AUTOSAR XML (schema 4-3-0)
standard types defined: boolean, uint16, uint32, uint64, uint8, boolean_DataConstr, uint16_DataConstr, uint32_DataConstr, uint64_DataConstr, uint8_DataConstr
package /ComponentTypes/MappingSets
  data type mapping set APP_data_mapping
    data-type-maps:
      application-data-type=APP_CallID, implementation-data-type=uint64
      application-data-type=App_Curr, implementation-data-type=uint16
      application-data-type=App_DutyRat, implementation-data-type=uint16
      application-data-type=App_FltSts, implementation-data-type=uint8
      application-data-type=App_HornActSts, implementation-data-type=uint8
      application-data-type=App_HornCmd, implementation-data-type=uint8
      application-data-type=APP_HornCtrlMode1, implementation-data-type=Impl_HornCtrlMode1
      application-data-type=App_HornHonkMode, implementation-data-type=uint8
      application-data-type=App_HornOperCmd, implementation-data-type=uint8
      application-data-type=APP_HornPeriodMode, implementation-data-type=Impl_HornPeriod
      application-data-type=APP_HornTimes, implementation-data-type=uint8
      application-data-type=APP_OffDuration, implementation-data-type=uint32
      application-data-type=APP_OnDuration, implementation-data-type=uint32
      application-data-type=APP_OperSts, implementation-data-type=uint8
      application-data-type=APP_Prio, implementation-data-type=uint8
      application-data-type=App_ReturnCode, implementation-data-type=uint8
      application-data-type=App_SrvOperSts1, implementation-data-type=Impl_SrvOperSts_Struct
      application-data-type=APP_TimeStamp, implementation-data-type=uint64
      application-data-type=App_Volt, implementation-data-type=uint16
      application-data-type=APP_Boolean, implementation-data-type=boolean
      application-data-type=APP_Uint8, implementation-data-type=uint8
package /DataTypes
  10 x app type, all with sw-calibration-access=READ-ONLY:
    APP_Boolean: category=BOOLEAN, compu {0=FALSE, 1=TRUE}
    APP_CallID: category=VALUE
    App_HornHonkMode: category=VALUE, compu {0=STOP, 1=START, 2=ALERT, 255=INVALID}
    APP_HornTimes: category=VALUE
    APP_OffDuration: category=VALUE
    APP_OnDuration: category=VALUE
    APP_OperSts: category=VALUE
    APP_Prio: category=VALUE
    APP_TimeStamp: category=VALUE
    APP_Uint8: category=VALUE
  application record data type APP_HornCtrlMode1: category=STRUCTURE, sw-calibration-access=READ-ONLY
    5 x application record element:
      CallID: category=VALUE, type=APP_CallID
      TimeStamp: category=VALUE, type=APP_TimeStamp
      Prio: category=VALUE, type=APP_Prio
      HornHonkMode: category=VALUE, type=App_HornHonkMode
      HornPeriodMode: category=STRUCTURE, type=APP_HornPeriodMode
  application record data type APP_HornPeriodMode: category=STRUCTURE, sw-calibration-access=READ-ONLY
    application record element OnDuration: category=VALUE, type=APP_OnDuration
    application record element OffDuration: category=VALUE, type=APP_OffDuration
    application record element HornTimes: category=VALUE, type=APP_HornTimes
  application record data type App_SrvOperSts1: category=STRUCTURE, sw-calibration-access=READ-ONLY
    4 x application record element, all with category=VALUE:
      CallID: type=APP_CallID
      TimeStamp: type=APP_TimeStamp
      Prio: type=APP_Prio
      OperSts: type=APP_OperSts
  impl type Impl_HornCtrlMode1: category=STRUCTURE, sw-calibration-access=READ-ONLY, type-emitter=RTE
    5 x element, all with category=TYPE_REFERENCE:
      CallID: implementation-data-type=uint64
      TimeStamp: implementation-data-type=uint64
      Prio: implementation-data-type=uint8
      HornHonkMode: compu {0=STOP, 1=START, 2=ALERT, 255=INVALID}, implementation-data-type=uint8
      HornPeriodMode: implementation-data-type=Impl_HornPeriod
  impl type Impl_HornPeriod: category=STRUCTURE, sw-calibration-access=READ-ONLY, type-emitter=RTE
    element OnDuration: implementation-data-type=uint32
    element OffDuration: implementation-data-type=uint32
    element HornTimes: compu {0=0次 (zero), 1=1次 (one), 2=2次 (two), 255=Invalid}, implementation-data-type=uint8
package /HORN_CTRL/ApplicationDataTypes
  8 x app type, all with category=VALUE:
    App_Curr: compu {phys=raw*0.01 for raw 0..65535; unit A}, range raw 0..65535, unit=A
    App_DutyRat: compu {phys=raw*0.1 for raw 0..1000}, range raw 0..1000, unit=-
    App_FltSts
    App_HornActSts: compu {0=HONK_OFF, 1=HONK_ON, 255=INVALID}, range raw 0..255, unit=-
    App_HornCmd: compu {0=STOP, 1=START, 2=ALERT, 255=INVALID}, range raw 0..255
    App_HornOperCmd: compu {0=OFF, 1=ON, 255=INVALID}, range raw 0..255
    App_ReturnCode
    App_Volt: compu {phys=raw*0.01 for raw 0..65535; unit V}, range raw 0..65535, unit=V
package /HORN_CTRL/Components
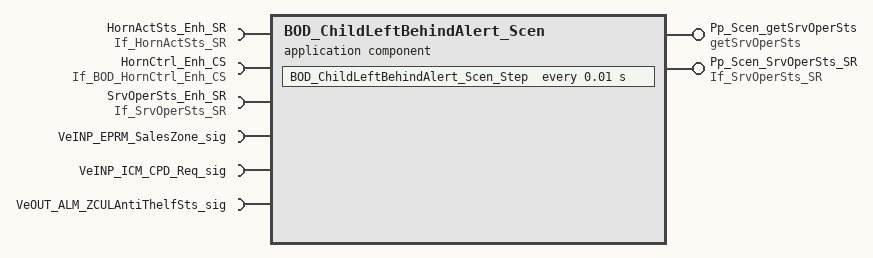
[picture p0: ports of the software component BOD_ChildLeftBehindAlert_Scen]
  application sw component type BOD_ChildLeftBehindAlert_Scen
    provide port Pp_Scen_getSrvOperSts: server-com-spec{operation=getSrvOperSts/getSrvOperSts, queue-length=1}, provided-interface=getSrvOperSts
    provide port Pp_Scen_SrvOperSts_SR: nonqueued-sender-com-spec{data-element=ntfSrvOperSts, init-value=fields=[CallID:0, TimeStamp:0, Prio:0, OperSts:0]}, provided-interface=If_SrvOperSts_SR
    6 x require port:
      HornActSts_Enh_SR: nonqueued-receiver-com-spec{data-element=ntfHornActSts, filter=data-filter-type=ALWAYS, init-value=0}, required-interface=If_HornActSts_SR
      HornCtrl_Enh_CS: required-interface=If_BOD_HornCtrl_Enh_CS
        required-com-specs:
          operation=getHornActSts, end-to-end-transformation-com-spec-props=disable-end-to-end-check=false
          operation=If_BOD_HornCtrl_Enh_CS/getSrvOperSts, end-to-end-transformation-com-spec-props=disable-end-to-end-check=false
          operation=rrHornCtrl, end-to-end-transformation-com-spec-props=disable-end-to-end-check=false
      SrvOperSts_Enh_SR: nonqueued-receiver-com-spec{data-element=ntfSrvOperSts, filter=data-filter-type=ALWAYS, init-value=fields=[TimeStamp:0, CallID:0, Prio:0, OperSts:0]}, required-interface=If_SrvOperSts_SR
      VeINP_EPRM_SalesZone_sig: nonqueued-receiver-com-spec{data-element=VeINP_EPRM_SalesZone_sig, filter=data-filter-type=ALWAYS, init-value=0}, required-interface=VeINP_EPRM_SalesZone_sig
      VeINP_ICM_CPD_Req_sig: nonqueued-receiver-com-spec{data-element=VeINP_ICM_CPD_Req_sig, filter=data-filter-type=ALWAYS, init-value=0}, required-interface=VeINP_ICM_CPD_Req_sig
      VeOUT_ALM_ZCULAntiThelfSts_sig: nonqueued-receiver-com-spec{data-element=VeOUT_ALM_ZCULAntiThelfSts_sig, filter=data-filter-type=ALWAYS, init-value=0}, required-interface=VeOUT_ALM_ZCULAntiThelfSts_sig
    behavior BOD_ChildLeftBehindAlert_Scen_InternalBehavior: data-type-mapping=APP_data_mapping, handle-termination-and-restart=NO-SUPPORT
      init event BOD_ChildLeftBehindAlert_Scen_InitEvent: start-on-event=BOD_ChildLeftBehindAlert_Scen_Init
      timing event TMT_BOD_ChildLeftBehindAlert_Scen_Step: start-on-event=BOD_ChildLeftBehindAlert_Scen_Step, period=0.01
      operation invoked event OIT_Pp_Scen_getSrvOperSts_getSrvOperSts_Pp_Scen_getSrvOperSts_getSrvOperSts: start-on-event=Pp_Scen_getSrvOperSts_getSrvOperSts, operation=Pp_Scen_getSrvOperSts.getSrvOperSts
      data received event DRT_Runnable_NTF_Pp_HornActSts_SR_ntfHornActSts: start-on-event=BOD_ChildLeftBehindAlert_Scen_InternalBehavior/Runnable_NTF, data=HornActSts_Enh_SR.ntfHornActSts
      data received event DRT_Runnable_NTF_Rp_SrvOperSts_SR_ntfSrvOperSts: start-on-event=BOD_ChildLeftBehindAlert_Scen_InternalBehavior/Runnable_NTF, data=SrvOperSts_Enh_SR.ntfSrvOperSts
      4 x runnable:
        BOD_ChildLeftBehindAlert_Scen_Init
        BOD_ChildLeftBehindAlert_Scen_Step
          data-receive-point-by-arguments:
            access REC_VeINP_EPRM_SalesZone_sig_VeINP_EPRM_SalesZone_sig: accessed-variable=VeINP_EPRM_SalesZone_sig.VeINP_EPRM_SalesZone_sig
            access REC_VeINP_ICM_CPD_Req_sig_VeINP_ICM_CPD_Req_sig: accessed-variable=VeINP_ICM_CPD_Req_sig.VeINP_ICM_CPD_Req_sig
            access REC_VeOUT_ALM_ZCULAntiThelfSts_sig_VeOUT_ALM_ZCULAntiThelfSts_sig: accessed-variable=VeOUT_ALM_ZCULAntiThelfSts_sig.VeOUT_ALM_ZCULAntiThelfSts_sig
          data-send-points:
            access SEND_Pp_SrvOperSts_SR_ntfSrvOperSts: accessed-variable=Pp_Scen_SrvOperSts_SR.ntfSrvOperSts
          sync call SC_Rp_HornCtrl_Enh_CS_getHornActSts: operation=HornCtrl_Enh_CS.getHornActSts, timeout=0
          sync call SC_Rp_HornCtrl_Enh_CS_getSrvOperSts: operation=HornCtrl_Enh_CS.getSrvOperSts, timeout=0
          sync call SC_Rp_HornCtrl_Enh_CS_rrHornCtrl: operation=HornCtrl_Enh_CS.rrHornCtrl, timeout=0
        Pp_Scen_getSrvOperSts_getSrvOperSts
        Runnable_NTF
          data-receive-point-by-arguments:
            access REC_Pp_HornActSts_SR_ntfHornActSts: accessed-variable=HornActSts_Enh_SR.ntfHornActSts
            access REC_Rp_SrvOperSts_SR_ntfSrvOperSts: accessed-variable=SrvOperSts_Enh_SR.ntfSrvOperSts
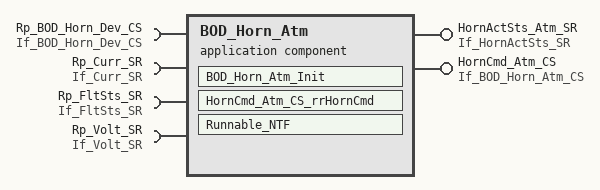
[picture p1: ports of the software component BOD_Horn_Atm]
  application sw component type BOD_Horn_Atm
    provide port HornActSts_Atm_SR: nonqueued-sender-com-spec{data-element=ntfHornActSts, init-value=0}, provided-interface=If_HornActSts_SR
    provide port HornCmd_Atm_CS: server-com-spec{operation=rrHornCmd, queue-length=1, end-to-end-transformation-com-spec-props=disable-end-to-end-check=false}, provided-interface=If_BOD_Horn_Atm_CS
    4 x require port:
      Rp_BOD_Horn_Dev_CS: client-com-spec=operation=rrHornOperCmd, required-interface=If_BOD_Horn_Dev_CS
      Rp_Curr_SR: nonqueued-receiver-com-spec{data-element=ntfCurr, filter=data-filter-type=ALWAYS, init-value=0}, required-interface=If_Curr_SR
      Rp_FltSts_SR: nonqueued-receiver-com-spec{data-element=ntfFltSts, filter=data-filter-type=ALWAYS, init-value=0}, required-interface=If_FltSts_SR
      Rp_Volt_SR: nonqueued-receiver-com-spec{data-element=ntfVolt, filter=data-filter-type=ALWAYS, init-value=0}, required-interface=If_Volt_SR
    behavior IB_BOD_Horn_Atm: data-type-mapping=APP_data_mapping, handle-termination-and-restart=NO-SUPPORT
      init event BOD_Horn_Atm_InitEvent: start-on-event=BOD_Horn_Atm_Init
      operation invoked event OIT_HornCmd_Atm_CS_rrHornCmd_HornCmd_Atm_CS_rrHornCmd: start-on-event=HornCmd_Atm_CS_rrHornCmd, operation=HornCmd_Atm_CS.rrHornCmd
      data received event DRT_Runnable_NTF_Rp_Curr_SR_ntfCurr: start-on-event=IB_BOD_Horn_Atm/Runnable_NTF, data=Rp_Curr_SR.ntfCurr
      data received event DRT_Runnable_NTF_Rp_FltSts_SR_ntfFltSts: start-on-event=IB_BOD_Horn_Atm/Runnable_NTF, data=Rp_FltSts_SR.ntfFltSts
      data received event DRT_Runnable_NTF_Rp_Volt_SR_ntfVolt: start-on-event=IB_BOD_Horn_Atm/Runnable_NTF, data=Rp_Volt_SR.ntfVolt
      runnable BOD_Horn_Atm_Init
      runnable HornCmd_Atm_CS_rrHornCmd
      runnable Runnable_NTF
        data-receive-point-by-arguments:
          access REC_Rp_Curr_SR_ntfCurr: accessed-variable=Rp_Curr_SR.ntfCurr
          access REC_Rp_FltSts_SR_ntfFltSts: accessed-variable=Rp_FltSts_SR.ntfFltSts
          access REC_Rp_Volt_SR_ntfVolt: accessed-variable=Rp_Volt_SR.ntfVolt
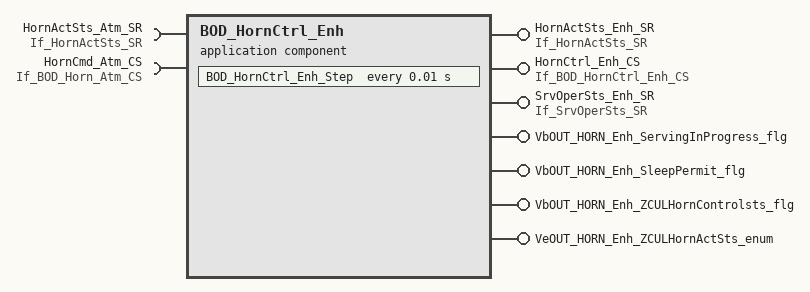
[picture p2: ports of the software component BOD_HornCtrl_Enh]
  application sw component type BOD_HornCtrl_Enh
    7 x provide port:
      HornActSts_Enh_SR: nonqueued-sender-com-spec{data-element=ntfHornActSts, transmission-acknowledge=timeout=0.5, init-value=0}, provided-interface=If_HornActSts_SR
      HornCtrl_Enh_CS: provided-interface=If_BOD_HornCtrl_Enh_CS
        provided-com-specs:
          operation=getHornActSts, queue-length=1, end-to-end-transformation-com-spec-props=disable-end-to-end-check=false
          operation=If_BOD_HornCtrl_Enh_CS/getSrvOperSts, queue-length=1, end-to-end-transformation-com-spec-props=disable-end-to-end-check=false
          operation=rrHornCtrl, queue-length=1, end-to-end-transformation-com-spec-props=disable-end-to-end-check=false
      SrvOperSts_Enh_SR: nonqueued-sender-com-spec{data-element=ntfSrvOperSts, handle-out-of-range=DEFAULT, transmission-acknowledge=timeout=0, init-value=fields=[TimeStamp:0, CallID:0, Prio:0, OperSts:0]}, provided-interface=If_SrvOperSts_SR
      VbOUT_HORN_Enh_ServingInProgress_flg: nonqueued-sender-com-spec{data-element=VbOUT_HORN_Enh_ServingInProgress_flg, init-value=0}, provided-interface=VbOUT_HORN_Enh_ServingInProgress_flg
      VbOUT_HORN_Enh_SleepPermit_flg: nonqueued-sender-com-spec{data-element=VbOUT_HORN_Enh_SleepPermit_flg, init-value=0}, provided-interface=VbOUT_HORN_Enh_SleepPermit_flg
      VbOUT_HORN_Enh_ZCULHornControlsts_flg: nonqueued-sender-com-spec{data-element=VbOUT_HORN_Enh_ZCULHornControlsts_flg, init-value=0}, provided-interface=VbOUT_HORN_Enh_ZCULHornControlsts_flg
      VeOUT_HORN_Enh_ZCULHornActSts_enum: nonqueued-sender-com-spec{data-element=VeOUT_HORN_Enh_ZCULHornActSts_enum, init-value=0}, provided-interface=VeOUT_HORN_Enh_ZCULHornActSts_enum
    require port HornActSts_Atm_SR: nonqueued-receiver-com-spec{data-element=ntfHornActSts, filter=data-filter-type=ALWAYS, init-value=0}, required-interface=If_HornActSts_SR
    require port HornCmd_Atm_CS: client-com-spec{operation=rrHornCmd, end-to-end-transformation-com-spec-props=disable-end-to-end-check=false}, required-interface=If_BOD_Horn_Atm_CS
    behavior IB_BOD_HornCtrl_Enh: data-type-mapping=APP_data_mapping, handle-termination-and-restart=NO-SUPPORT
      init event BOD_HornCtrl_Enh_InitEvent: start-on-event=BOD_HornCtrl_Enh_Init
      timing event TMT_Runnable: start-on-event=BOD_HornCtrl_Enh_Step, period=0.01
      operation invoked event OIT_HornCtrl_Enh_CS_getHornActSts_HornCtrl_Enh_CS_getHornActSts: start-on-event=HornCtrl_Enh_CS_getHornActSts, operation=HornCtrl_Enh_CS.getHornActSts
      operation invoked event OIT_HornCtrl_Enh_CS_getSrvOperSts_HornCtrl_Enh_CS_getSrvOperSts: start-on-event=HornCtrl_Enh_CS_getSrvOperSts, operation=HornCtrl_Enh_CS.getSrvOperSts
      operation invoked event OIT_HornCtrl_Enh_CS_rrHornCtrl_HornCtrl_Enh_CS_rrHornCtrl: start-on-event=HornCtrl_Enh_CS_rrHornCtrl, operation=HornCtrl_Enh_CS.rrHornCtrl
      data received event DRT_Runnable_NTF_Rp_Horn_Atm_SR_ntfHornActSts: start-on-event=IB_BOD_HornCtrl_Enh/Runnable_NTF, data=HornActSts_Atm_SR.ntfHornActSts
      6 x runnable:
        BOD_HornCtrl_Enh_Init
        BOD_HornCtrl_Enh_Step
          data-send-points:
            6 x access:
              SEND_Pp_HornActSts_SR_ntfHornActSts: accessed-variable=HornActSts_Enh_SR.ntfHornActSts
              SEND_Pp_SrvOperSts_SR_ntfSrvOperSts: accessed-variable=SrvOperSts_Enh_SR.ntfSrvOperSts
              SEND_VbOUT_HORN_Enh_ServingInProgress_flg_VbOUT_HORN_Enh_ServingInProgress_flg: accessed-variable=VbOUT_HORN_Enh_ServingInProgress_flg.VbOUT_HORN_Enh_ServingInProgress_flg
              SEND_VbOUT_HORN_Enh_SleepPermit_flg_VbOUT_HORN_Enh_SleepPermit_flg: accessed-variable=VbOUT_HORN_Enh_SleepPermit_flg.VbOUT_HORN_Enh_SleepPermit_flg
              SEND_VbOUT_HORN_Enh_ZCULHornControlsts_flg_VbOUT_HORN_Enh_ZCULHornControlsts_flg: accessed-variable=VbOUT_HORN_Enh_ZCULHornControlsts_flg.VbOUT_HORN_Enh_ZCULHornControlsts_flg
              SEND_VeOUT_HORN_Enh_ZCULHornActSts_enum_VeOUT_HORN_Enh_ZCULHornActSts_enum: accessed-variable=VeOUT_HORN_Enh_ZCULHornActSts_enum.VeOUT_HORN_Enh_ZCULHornActSts_enum
          sync call SC_Rp_Horn_Atm_CS_rrHornCmd: operation=HornCmd_Atm_CS.rrHornCmd, timeout=0
        HornCtrl_Enh_CS_getHornActSts
        HornCtrl_Enh_CS_getSrvOperSts
        HornCtrl_Enh_CS_rrHornCtrl
        Runnable_NTF
          data-receive-point-by-arguments:
            access REC_Rp_Horn_Atm_SR_ntfHornActSts: accessed-variable=HornActSts_Atm_SR.ntfHornActSts
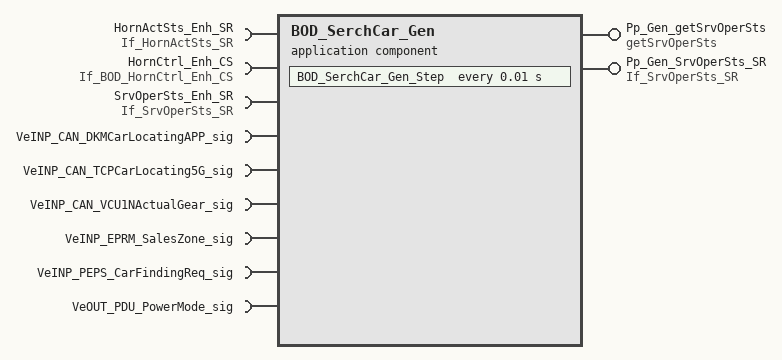
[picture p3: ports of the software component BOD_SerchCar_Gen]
  application sw component type BOD_SerchCar_Gen
    provide port Pp_Gen_getSrvOperSts: server-com-spec{operation=getSrvOperSts/getSrvOperSts, queue-length=1}, provided-interface=getSrvOperSts
    provide port Pp_Gen_SrvOperSts_SR: nonqueued-sender-com-spec{data-element=ntfSrvOperSts, init-value=fields=[CallID:0, TimeStamp:0, Prio:0, OperSts:0]}, provided-interface=If_SrvOperSts_SR
    9 x require port:
      HornActSts_Enh_SR: nonqueued-receiver-com-spec{data-element=ntfHornActSts, filter=data-filter-type=ALWAYS, init-value=0}, required-interface=If_HornActSts_SR
      HornCtrl_Enh_CS: required-interface=If_BOD_HornCtrl_Enh_CS
        required-com-specs:
          operation=getHornActSts, end-to-end-transformation-com-spec-props=disable-end-to-end-check=false
          operation=If_BOD_HornCtrl_Enh_CS/getSrvOperSts, end-to-end-transformation-com-spec-props=disable-end-to-end-check=false
          operation=rrHornCtrl, end-to-end-transformation-com-spec-props=disable-end-to-end-check=false
      SrvOperSts_Enh_SR: nonqueued-receiver-com-spec{data-element=ntfSrvOperSts, filter=data-filter-type=ALWAYS, init-value=fields=[TimeStamp:0, CallID:0, Prio:0, OperSts:0]}, required-interface=If_SrvOperSts_SR
      VeINP_CAN_DKMCarLocatingAPP_sig: nonqueued-receiver-com-spec{data-element=VeINP_CAN_DKMCarLocatingAPP_sig, filter=data-filter-type=ALWAYS, init-value=0}, required-interface=VeINP_CAN_DKMCarLocatingAPP_sig
      VeINP_CAN_TCPCarLocating5G_sig: nonqueued-receiver-com-spec{data-element=VeINP_CAN_TCPCarLocating5G_sig, filter=data-filter-type=ALWAYS, init-value=0}, required-interface=VeINP_CAN_TCPCarLocating5G_sig
      VeINP_CAN_VCU1NActualGear_sig: nonqueued-receiver-com-spec{data-element=VeINP_CAN_VCU1NActualGear_sig, filter=data-filter-type=ALWAYS, init-value=0}, required-interface=VeINP_CAN_VCU1NActualGear_sig
      VeINP_EPRM_SalesZone_sig: nonqueued-receiver-com-spec{data-element=VeINP_EPRM_SalesZone_sig, filter=data-filter-type=ALWAYS, init-value=0}, required-interface=VeINP_EPRM_SalesZone_sig
      VeINP_PEPS_CarFindingReq_sig: nonqueued-receiver-com-spec{data-element=VeINP_PEPS_CarFindingReq_sig, filter=data-filter-type=ALWAYS, init-value=0}, required-interface=VeINP_PEPS_CarFindingReq_sig
      VeOUT_PDU_PowerMode_sig: nonqueued-receiver-com-spec{data-element=VeOUT_PDU_PowerMode_sig, filter=data-filter-type=ALWAYS, init-value=0}, required-interface=VeOUT_PDU_PowerMode_sig
    behavior BOD_SerchCar_Gen_InternalBehavior: data-type-mapping=APP_data_mapping, handle-termination-and-restart=NO-SUPPORT
      init event BOD_SerchCar_Gen_InitEvent: start-on-event=BOD_SerchCar_Gen_Init
      timing event TMT_Runnable_1: start-on-event=BOD_SerchCar_Gen_Step, period=0.01
      operation invoked event OIT_Pp_Gen_getSrvOperSts_getSrvOperSts_Pp_Gen_getSrvOperSts_getSrvOperSts: start-on-event=Pp_Gen_getSrvOperSts_getSrvOperSts, operation=Pp_Gen_getSrvOperSts.getSrvOperSts
      data received event DRT_Runnable_Rp_HornActSts_SR_ntfHornActSts: start-on-event=BOD_SerchCar_Gen_InternalBehavior/Runnable_NTF, data=HornActSts_Enh_SR.ntfHornActSts
      data received event DRT_Runnable_Rp_SrvOperSts_SR_ntfSrvOperSts: start-on-event=BOD_SerchCar_Gen_InternalBehavior/Runnable_NTF, data=SrvOperSts_Enh_SR.ntfSrvOperSts
      4 x runnable:
        BOD_SerchCar_Gen_Init
        BOD_SerchCar_Gen_Step
          data-receive-point-by-arguments:
            6 x access:
              REC_VeINP_CAN_DKMCarLocatingAPP_sig_VeINP_CAN_DKMCarLocatingAPP_sig: accessed-variable=VeINP_CAN_DKMCarLocatingAPP_sig.VeINP_CAN_DKMCarLocatingAPP_sig
              REC_VeINP_CAN_TCPCarLocating5G_sig_VeINP_CAN_TCPCarLocating5G_sig: accessed-variable=VeINP_CAN_TCPCarLocating5G_sig.VeINP_CAN_TCPCarLocating5G_sig
              REC_VeINP_CAN_VCU1NActualGear_sig_VeINP_CAN_VCU1NActualGear_sig: accessed-variable=VeINP_CAN_VCU1NActualGear_sig.VeINP_CAN_VCU1NActualGear_sig
              REC_VeINP_EPRM_SalesZone_sig_VeINP_EPRM_SalesZone_sig: accessed-variable=VeINP_EPRM_SalesZone_sig.VeINP_EPRM_SalesZone_sig
              REC_VeINP_PEPS_CarFindingReq_sig_VeINP_PEPS_CarFindingReq_sig: accessed-variable=VeINP_PEPS_CarFindingReq_sig.VeINP_PEPS_CarFindingReq_sig
              REC_VeOUT_PDU_PowerMode_sig_VeOUT_PDU_PowerMode_sig: accessed-variable=VeOUT_PDU_PowerMode_sig.VeOUT_PDU_PowerMode_sig
          data-send-points:
            access SEND_Pp_SrvOperSts_SR_ntfSrvOperSts: accessed-variable=Pp_Gen_SrvOperSts_SR.ntfSrvOperSts
          sync call SC_Rp_HornCtrl_Enh_CS_getHornActSts: operation=HornCtrl_Enh_CS.getHornActSts, timeout=0
          sync call SC_Rp_HornCtrl_Enh_CS_getSrvOperSts: operation=HornCtrl_Enh_CS.getSrvOperSts, timeout=0
          sync call SC_Rp_HornCtrl_Enh_CS_rrHornCtrl: operation=HornCtrl_Enh_CS.rrHornCtrl, timeout=0
        Pp_Gen_getSrvOperSts_getSrvOperSts
        Runnable_NTF
          data-receive-point-by-arguments:
            access REC_Rp_HornActSts_SR_ntfHornActSts: accessed-variable=HornActSts_Enh_SR.ntfHornActSts
            access REC_Rp_SrvOperSts_SR_ntfSrvOperSts: accessed-variable=SrvOperSts_Enh_SR.ntfSrvOperSts
  4 x swc implementation:
    BOD_ChildLeftBehindAlert_Scen_Implementation: behavior=BOD_ChildLeftBehindAlert_Scen_InternalBehavior
      code-descriptors:
        code Default: artifact-descriptors=autosar-engineering-object={short-label=Default, category=SWSRC}
    BOD_Horn_Atm_Implementation: behavior=IB_BOD_Horn_Atm
      code-descriptors:
        code Default: artifact-descriptors=autosar-engineering-object=category=SWSRC
    BOD_HornCtrl_Enh_Implementation: behavior=IB_BOD_HornCtrl_Enh
      code-descriptors:
        code Default: artifact-descriptors=autosar-engineering-object=category=SWSRC
    BOD_SerchCar_Gen_Implementation: behavior=BOD_SerchCar_Gen_InternalBehavior
      code-descriptors:
        code Default: artifact-descriptors=autosar-engineering-object={short-label=Default, category=SWSRC}
package /HORN_CTRL/ImplementationDataTypes
  impl type Impl_SrvOperSts_Struct: category=STRUCTURE
    4 x element, all with category=TYPE_REFERENCE:
      CallID: implementation-data-type=uint64
      TimeStamp: implementation-data-type=uint64
      Prio: implementation-data-type=uint8
      OperSts: implementation-data-type=uint8
package /HORN_CTRL/Interfaces
  client server interface If_BOD_Horn_Atm_CS
    operation rrHornCmd
      arg HornCmd: type=App_HornCmd, direction=IN, server-argument-impl-policy=USE-ARGUMENT-TYPE
      arg ReturnCode: type=App_ReturnCode, direction=OUT, server-argument-impl-policy=USE-ARGUMENT-TYPE
  client server interface If_BOD_Horn_Dev_CS
    operation rrHornOperCmd
      arg HornOperCmd: type=App_HornOperCmd, direction=IN, server-argument-impl-policy=USE-ARGUMENT-TYPE
      arg DutyRat: type=App_DutyRat, direction=IN, server-argument-impl-policy=USE-ARGUMENT-TYPE
      arg ReturnCode: type=App_ReturnCode, direction=OUT, server-argument-impl-policy=USE-ARGUMENT-TYPE
  client server interface If_BOD_HornCtrl_Enh_CS
    operation getHornActSts
      arg HornActSts: type=App_HornActSts, direction=OUT, server-argument-impl-policy=USE-ARGUMENT-TYPE
    operation getSrvOperSts
      arg SrvOperSts: type=App_SrvOperSts1, direction=OUT, server-argument-impl-policy=USE-ARGUMENT-TYPE
    operation rrHornCtrl
      arg HornCtrlMode: type=APP_HornCtrlMode1, direction=IN, server-argument-impl-policy=USE-ARGUMENT-TYPE
      arg ReturnCode: type=App_ReturnCode, direction=OUT, server-argument-impl-policy=USE-ARGUMENT-TYPE
  5 x sender receiver interface:
    If_Curr_SR: invalidation-policy{data-element=ntfCurr, handle-invalid=DONT-INVALIDATE}
      data ntfCurr: type=App_Curr
    If_FltSts_SR: invalidation-policy{data-element=ntfFltSts, handle-invalid=DONT-INVALIDATE}
      data ntfFltSts: type=App_FltSts
    If_HornActSts_SR: invalidation-policy{data-element=ntfHornActSts, handle-invalid=DONT-INVALIDATE}
      data ntfHornActSts: type=App_HornActSts
    If_SrvOperSts_SR: invalidation-policy{data-element=ntfSrvOperSts, handle-invalid=DONT-INVALIDATE}
      data ntfSrvOperSts: type=App_SrvOperSts1
    If_Volt_SR: invalidation-policy{data-element=ntfVolt, handle-invalid=DONT-INVALIDATE}
      data ntfVolt: type=App_Volt
package /HORN_CTRL/System
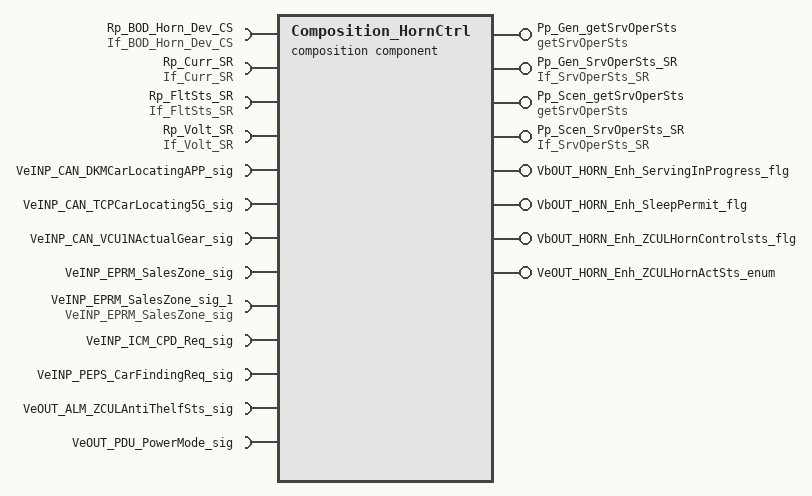
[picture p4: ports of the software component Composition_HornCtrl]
  composition sw component type Composition_HornCtrl
    8 x provide port:
      Pp_Gen_getSrvOperSts: server-com-spec{operation=getSrvOperSts/getSrvOperSts, queue-length=1}, provided-interface=getSrvOperSts
      Pp_Gen_SrvOperSts_SR: nonqueued-sender-com-spec{data-element=ntfSrvOperSts, init-value=fields=[CallID:0, TimeStamp:0, Prio:0, OperSts:0]}, provided-interface=If_SrvOperSts_SR
      Pp_Scen_getSrvOperSts: server-com-spec{operation=getSrvOperSts/getSrvOperSts, queue-length=1}, provided-interface=getSrvOperSts
      Pp_Scen_SrvOperSts_SR: nonqueued-sender-com-spec{data-element=ntfSrvOperSts, init-value=fields=[CallID:0, TimeStamp:0, Prio:0, OperSts:0]}, provided-interface=If_SrvOperSts_SR
      VbOUT_HORN_Enh_ServingInProgress_flg: nonqueued-sender-com-spec{data-element=VbOUT_HORN_Enh_ServingInProgress_flg, init-value=0}, provided-interface=VbOUT_HORN_Enh_ServingInProgress_flg
      VbOUT_HORN_Enh_SleepPermit_flg: nonqueued-sender-com-spec{data-element=VbOUT_HORN_Enh_SleepPermit_flg, init-value=0}, provided-interface=VbOUT_HORN_Enh_SleepPermit_flg
      VbOUT_HORN_Enh_ZCULHornControlsts_flg: nonqueued-sender-com-spec{data-element=VbOUT_HORN_Enh_ZCULHornControlsts_flg, init-value=0}, provided-interface=VbOUT_HORN_Enh_ZCULHornControlsts_flg
      VeOUT_HORN_Enh_ZCULHornActSts_enum: nonqueued-sender-com-spec{data-element=VeOUT_HORN_Enh_ZCULHornActSts_enum, init-value=0}, provided-interface=VeOUT_HORN_Enh_ZCULHornActSts_enum
    13 x require port:
      Rp_BOD_Horn_Dev_CS: client-com-spec=operation=rrHornOperCmd, required-interface=If_BOD_Horn_Dev_CS
      Rp_Curr_SR: nonqueued-receiver-com-spec{data-element=ntfCurr, filter=data-filter-type=ALWAYS, init-value=0}, required-interface=If_Curr_SR
      Rp_FltSts_SR: nonqueued-receiver-com-spec{data-element=ntfFltSts, filter=data-filter-type=ALWAYS, init-value=0}, required-interface=If_FltSts_SR
      Rp_Volt_SR: nonqueued-receiver-com-spec{data-element=ntfVolt, filter=data-filter-type=ALWAYS, init-value=0}, required-interface=If_Volt_SR
      VeINP_CAN_DKMCarLocatingAPP_sig: nonqueued-receiver-com-spec{data-element=VeINP_CAN_DKMCarLocatingAPP_sig, filter=data-filter-type=ALWAYS, init-value=0}, required-interface=VeINP_CAN_DKMCarLocatingAPP_sig
      VeINP_CAN_TCPCarLocating5G_sig: nonqueued-receiver-com-spec{data-element=VeINP_CAN_TCPCarLocating5G_sig, filter=data-filter-type=ALWAYS, init-value=0}, required-interface=VeINP_CAN_TCPCarLocating5G_sig
      VeINP_CAN_VCU1NActualGear_sig: nonqueued-receiver-com-spec{data-element=VeINP_CAN_VCU1NActualGear_sig, filter=data-filter-type=ALWAYS, init-value=0}, required-interface=VeINP_CAN_VCU1NActualGear_sig
      VeINP_EPRM_SalesZone_sig: nonqueued-receiver-com-spec{data-element=VeINP_EPRM_SalesZone_sig, filter=data-filter-type=ALWAYS, init-value=0}, required-interface=VeINP_EPRM_SalesZone_sig
      VeINP_EPRM_SalesZone_sig_1: nonqueued-receiver-com-spec{data-element=VeINP_EPRM_SalesZone_sig, filter=data-filter-type=ALWAYS, init-value=0}, required-interface=VeINP_EPRM_SalesZone_sig
      VeINP_ICM_CPD_Req_sig: nonqueued-receiver-com-spec{data-element=VeINP_ICM_CPD_Req_sig, filter=data-filter-type=ALWAYS, init-value=0}, required-interface=VeINP_ICM_CPD_Req_sig
      VeINP_PEPS_CarFindingReq_sig: nonqueued-receiver-com-spec{data-element=VeINP_PEPS_CarFindingReq_sig, filter=data-filter-type=ALWAYS, init-value=0}, required-interface=VeINP_PEPS_CarFindingReq_sig
      VeOUT_ALM_ZCULAntiThelfSts_sig: nonqueued-receiver-com-spec{data-element=VeOUT_ALM_ZCULAntiThelfSts_sig, filter=data-filter-type=ALWAYS, init-value=0}, required-interface=VeOUT_ALM_ZCULAntiThelfSts_sig
      VeOUT_PDU_PowerMode_sig: nonqueued-receiver-com-spec{data-element=VeOUT_PDU_PowerMode_sig, filter=data-filter-type=ALWAYS, init-value=0}, required-interface=VeOUT_PDU_PowerMode_sig
    4 x component:
      Atm_Inst: type=BOD_Horn_Atm
      Enh_Inst: type=BOD_HornCtrl_Enh
      Gen_Inst1: type=BOD_ChildLeftBehindAlert_Scen
      Gen_Inst2: type=BOD_SerchCar_Gen
    connect Atm_Inst.HornActSts_Atm_SR -> Enh_Inst.HornActSts_Atm_SR
    connect Atm_Inst.HornCmd_Atm_CS -> Enh_Inst.HornCmd_Atm_CS
    connect Enh_Inst.HornActSts_Enh_SR -> Gen_Inst1.HornActSts_Enh_SR
    connect Enh_Inst.HornCtrl_Enh_CS -> Gen_Inst1.HornCtrl_Enh_CS
    connect Enh_Inst.SrvOperSts_Enh_SR -> Gen_Inst1.SrvOperSts_Enh_SR
    connect Enh_Inst.HornActSts_Enh_SR -> Gen_Inst2.HornActSts_Enh_SR
    connect Enh_Inst.HornCtrl_Enh_CS -> Gen_Inst2.HornCtrl_Enh_CS
    connect Enh_Inst.SrvOperSts_Enh_SR -> Gen_Inst2.SrvOperSts_Enh_SR
    delegate Gen_Inst2.Pp_Gen_getSrvOperSts <-> outer port Composition_HornCtrl/Pp_Gen_getSrvOperSts
    delegate Gen_Inst2.Pp_Gen_SrvOperSts_SR <-> outer port Composition_HornCtrl/Pp_Gen_SrvOperSts_SR
    delegate Gen_Inst1.Pp_Scen_getSrvOperSts <-> outer port Composition_HornCtrl/Pp_Scen_getSrvOperSts
    delegate Gen_Inst1.Pp_Scen_SrvOperSts_SR <-> outer port Composition_HornCtrl/Pp_Scen_SrvOperSts_SR
    delegate Atm_Inst.Rp_BOD_Horn_Dev_CS <-> outer port Composition_HornCtrl/Rp_BOD_Horn_Dev_CS
    delegate Atm_Inst.Rp_Curr_SR <-> outer port Composition_HornCtrl/Rp_Curr_SR
    delegate Atm_Inst.Rp_FltSts_SR <-> outer port Composition_HornCtrl/Rp_FltSts_SR
    delegate Atm_Inst.Rp_Volt_SR <-> outer port Composition_HornCtrl/Rp_Volt_SR
    delegate Enh_Inst.VbOUT_HORN_Enh_ServingInProgress_flg <-> outer port Composition_HornCtrl/VbOUT_HORN_Enh_ServingInProgress_flg
    delegate Enh_Inst.VbOUT_HORN_Enh_SleepPermit_flg <-> outer port Composition_HornCtrl/VbOUT_HORN_Enh_SleepPermit_flg
    delegate Enh_Inst.VbOUT_HORN_Enh_ZCULHornControlsts_flg <-> outer port Composition_HornCtrl/VbOUT_HORN_Enh_ZCULHornControlsts_flg
    delegate Gen_Inst2.VeINP_CAN_DKMCarLocatingAPP_sig <-> outer port Composition_HornCtrl/VeINP_CAN_DKMCarLocatingAPP_sig
    delegate Gen_Inst2.VeINP_CAN_TCPCarLocating5G_sig <-> outer port Composition_HornCtrl/VeINP_CAN_TCPCarLocating5G_sig
    delegate Gen_Inst2.VeINP_CAN_VCU1NActualGear_sig <-> outer port Composition_HornCtrl/VeINP_CAN_VCU1NActualGear_sig
    delegate Gen_Inst2.VeINP_EPRM_SalesZone_sig <-> outer port Composition_HornCtrl/VeINP_EPRM_SalesZone_sig
    delegate Gen_Inst1.VeINP_EPRM_SalesZone_sig <-> outer port VeINP_EPRM_SalesZone_sig_1
    delegate Gen_Inst1.VeINP_ICM_CPD_Req_sig <-> outer port Composition_HornCtrl/VeINP_ICM_CPD_Req_sig
    delegate Gen_Inst2.VeINP_PEPS_CarFindingReq_sig <-> outer port Composition_HornCtrl/VeINP_PEPS_CarFindingReq_sig
    delegate Gen_Inst1.VeOUT_ALM_ZCULAntiThelfSts_sig <-> outer port Composition_HornCtrl/VeOUT_ALM_ZCULAntiThelfSts_sig
    delegate Enh_Inst.VeOUT_HORN_Enh_ZCULHornActSts_enum <-> outer port Composition_HornCtrl/VeOUT_HORN_Enh_ZCULHornActSts_enum
    delegate Gen_Inst2.VeOUT_PDU_PowerMode_sig <-> outer port Composition_HornCtrl/VeOUT_PDU_PowerMode_sig
package /HORN_CTRL/Units
  unit Unit_Ampere: display-name=A, factor-si-to-unit=1, offset-si-to-unit=0
  unit Unit_NoUnit: display-name=-, factor-si-to-unit=1, offset-si-to-unit=0
  unit Unit_Volt: display-name=V, factor-si-to-unit=1, offset-si-to-unit=0
package /PortInterfaces
  client server interface getSrvOperSts
    operation getSrvOperSts
      arg Response: type=App_SrvOperSts1, direction=OUT, server-argument-impl-policy=USE-ARGUMENT-TYPE
  12 x sender receiver interface:
    VbOUT_HORN_Enh_ServingInProgress_flg: invalidation-policy{data-element=VbOUT_HORN_Enh_ServingInProgress_flg, handle-invalid=DONT-INVALIDATE}
      data VbOUT_HORN_Enh_ServingInProgress_flg: type=APP_Boolean
    VbOUT_HORN_Enh_SleepPermit_flg: invalidation-policy{data-element=VbOUT_HORN_Enh_SleepPermit_flg, handle-invalid=DONT-INVALIDATE}
      data VbOUT_HORN_Enh_SleepPermit_flg: type=APP_Boolean
    VbOUT_HORN_Enh_ZCULHornControlsts_flg: invalidation-policy{data-element=VbOUT_HORN_Enh_ZCULHornControlsts_flg, handle-invalid=DONT-INVALIDATE}
      data VbOUT_HORN_Enh_ZCULHornControlsts_flg: type=APP_Boolean
    VeINP_CAN_DKMCarLocatingAPP_sig: invalidation-policy{data-element=VeINP_CAN_DKMCarLocatingAPP_sig, handle-invalid=DONT-INVALIDATE}
      data VeINP_CAN_DKMCarLocatingAPP_sig: type=APP_Uint8
    VeINP_CAN_TCPCarLocating5G_sig: invalidation-policy{data-element=VeINP_CAN_TCPCarLocating5G_sig, handle-invalid=DONT-INVALIDATE}
      data VeINP_CAN_TCPCarLocating5G_sig: type=APP_Uint8
    VeINP_CAN_VCU1NActualGear_sig: invalidation-policy{data-element=VeINP_CAN_VCU1NActualGear_sig, handle-invalid=DONT-INVALIDATE}
      data VeINP_CAN_VCU1NActualGear_sig: type=APP_Uint8
    VeINP_EPRM_SalesZone_sig: invalidation-policy{data-element=VeINP_EPRM_SalesZone_sig, handle-invalid=DONT-INVALIDATE}
      data VeINP_EPRM_SalesZone_sig: type=APP_Uint8
    VeINP_ICM_CPD_Req_sig: invalidation-policy{data-element=VeINP_ICM_CPD_Req_sig, handle-invalid=DONT-INVALIDATE}
      data VeINP_ICM_CPD_Req_sig: type=APP_Uint8
    VeINP_PEPS_CarFindingReq_sig: invalidation-policy{data-element=VeINP_PEPS_CarFindingReq_sig, handle-invalid=DONT-INVALIDATE}
      data VeINP_PEPS_CarFindingReq_sig: type=APP_Uint8
    VeOUT_ALM_ZCULAntiThelfSts_sig: invalidation-policy{data-element=VeOUT_ALM_ZCULAntiThelfSts_sig, handle-invalid=DONT-INVALIDATE}
      data VeOUT_ALM_ZCULAntiThelfSts_sig: type=APP_Uint8
    VeOUT_HORN_Enh_ZCULHornActSts_enum: invalidation-policy{data-element=VeOUT_HORN_Enh_ZCULHornActSts_enum, handle-invalid=DONT-INVALIDATE}
      data VeOUT_HORN_Enh_ZCULHornActSts_enum: type=APP_Boolean
    VeOUT_PDU_PowerMode_sig: invalidation-policy{data-element=VeOUT_PDU_PowerMode_sig, handle-invalid=DONT-INVALIDATE}
      data VeOUT_PDU_PowerMode_sig: type=APP_Uint8
